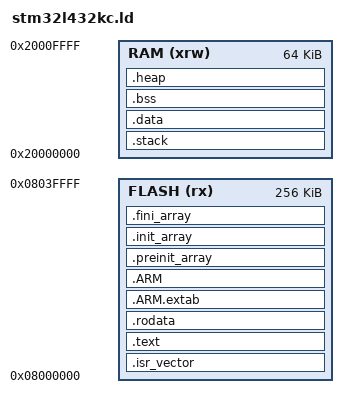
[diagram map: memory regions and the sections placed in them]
/* Entry point */
ENTRY(Reset_Handler)

/* Memory map */
MEMORY {
    RAM     (xrw)   : ORIGIN = 0x20000000,   LENGTH = 64K
    FLASH   (rx)    : ORIGIN = 0x8000000,   LENGTH = 256K
}

/* Stack and heap sizes */
STACK_SIZE = 4096;
HEAP_SIZE = 512;

/* Sections */
SECTIONS {
    .isr_vector : {
        . = ALIGN(4);
        KEEP(*(.isr_vector)) /* Startup code */
        . = ALIGN(4);
    } >FLASH

    .text : {
        . = ALIGN(4);
        *(.text)           /* .text sections (code) */
        *(.text*)          /* .text* sections (code) */
        *(.glue_7)         /* glue arm to thumb code */
        *(.glue_7t)        /* glue thumb to arm code */
        *(.eh_frame)

        KEEP (*(.init))
        KEEP (*(.fini))

        . = ALIGN(4);
        _etext = .;        /* define a global symbols at end of code */
    } >FLASH

    .rodata : {
        . = ALIGN(4);
        *(.rodata)         /* .rodata sections (constants, strings, etc.) */
        *(.rodata*)        /* .rodata* sections (constants, strings, etc.) */
        . = ALIGN(4);
    } >FLASH

    .ARM.extab : { 
        . = ALIGN(4);
        *(.ARM.extab* .gnu.linkonce.armextab.*)
        . = ALIGN(4);
    } >FLASH

    .ARM : {
        . = ALIGN(4);
        __exidx_start = .;
        *(.ARM.exidx*)
        __exidx_end = .;
        . = ALIGN(4);
    } >FLASH

    .preinit_array : {
        . = ALIGN(4);
        PROVIDE_HIDDEN (__preinit_array_start = .);
        KEEP (*(.preinit_array*))
        PROVIDE_HIDDEN (__preinit_array_end = .);
        . = ALIGN(4);
    } >FLASH

    .init_array : {
        . = ALIGN(4);
        PROVIDE_HIDDEN (__init_array_start = .);
        KEEP (*(SORT(.init_array.*)))
        KEEP (*(.init_array*))
        PROVIDE_HIDDEN (__init_array_end = .);
        . = ALIGN(4);
    } >FLASH

    .fini_array : {
        . = ALIGN(4);
        PROVIDE_HIDDEN (__fini_array_start = .);
        KEEP (*(SORT(.fini_array.*)))
        KEEP (*(.fini_array*))
        PROVIDE_HIDDEN (__fini_array_end = .);
        . = ALIGN(4);
    } >FLASH

    /* End of FLASH */
    _etext = .;

    .stack : {
        __stack_start__ = .;
        . = . + STACK_SIZE;
        . = ALIGN(4);
        __stack_end__ = .;
    } >RAM

    .data :  AT (_etext) {
        __data_load = LOADADDR (.data);
        __data_start = .;
        *(.data)           /* .data sections */
        *(.data*)          /* .data* sections */
        . = ALIGN(4);
        __data_end__ = .;
        _edata = __data_end__;
    } >RAM

    .bss : {
        __bss_start__ = .;
        *(.bss)
        *(.bss*)
        *(COMMON)
        . = ALIGN(4);
        _ebss = .;         /* define a global symbol at bss end */
        __bss_end__ = .;
    } >RAM

    PROVIDE ( end = _ebss );
    PROVIDE ( _end = _ebss );
    PROVIDE ( __end__ = _ebss );

    .heap : {
        __heap_start__ = .;
        . = . + HEAP_SIZE;
        . = ALIGN(4);
        __heap_end__ = .;
    } >RAM

    /* Remove information from the standard libraries */
    /DISCARD/ : {
        libc.a ( * )
        libm.a ( * )
        libgcc.a ( * )
    }

    .ARM.attributes 0 : { *(.ARM.attributes) }
}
